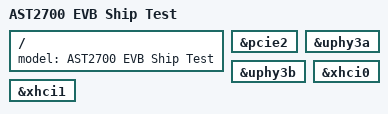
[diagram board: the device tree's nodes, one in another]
// SPDX-License-Identifier: GPL-2.0-or-later

#include "ast2700-evb.dts"

/ {
	model = "AST2700 EVB Ship Test";
};

&pcie2 {
	status = "okay";
};

&uphy3a {
	status = "okay";
};

&uphy3b {
	status = "okay";
};

&xhci0 {
	status = "okay";
};

&xhci1 {
	status = "okay";
};
